VERSION ""

NS_ :

BS_:

BU_: Gateway BCM DoorMaster Cluster HVAC

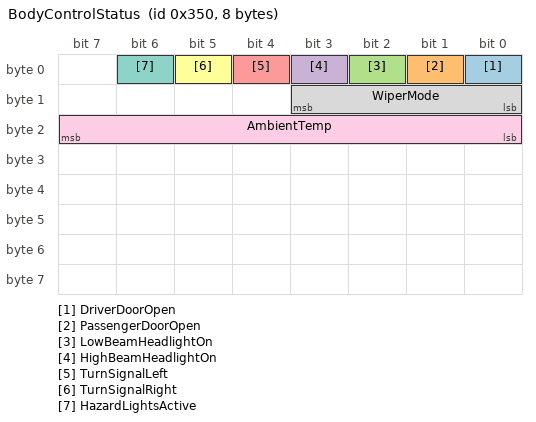
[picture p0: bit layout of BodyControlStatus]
BO_ 848 BodyControlStatus: 8 BCM
 SG_ DriverDoorOpen : 0|1@1+ (1,0) [0|1] "" Gateway
 SG_ PassengerDoorOpen : 1|1@1+ (1,0) [0|1] "" Gateway
 SG_ LowBeamHeadlightOn : 2|1@1+ (1,0) [0|1] "" Gateway
 SG_ HighBeamHeadlightOn : 3|1@1+ (1,0) [0|1] "" Gateway
 SG_ TurnSignalLeft : 4|1@1+ (1,0) [0|1] "" Gateway
 SG_ TurnSignalRight : 5|1@1+ (1,0) [0|1] "" Gateway
 SG_ HazardLightsActive : 6|1@1+ (1,0) [0|1] "" Gateway
 SG_ WiperMode : 8|4@1+ (1,0) [0|5] "" Gateway
 SG_ AmbientTemp : 16|8@1+ (0.5,-40) [-40|60] "degC" Gateway,Cluster

CM_ BO_ 848 "Body Control Module comfort, lighting, and entry state on Classical CAN 2.0B at 500 kbps.";
